# cyw20829 register map
Vendor: Infineon Technologies; Series: CYW20829; File version: 1.0
CPU: CM33 r0p1, little endian, MPU, no FPU, VTOR, 3 interrupt priority bits
Registers are 32-bit, read-write, reset 0x0 unless marked. A register's access mark holds for its fields unless they carry their own. Offsets are from the block's base; [hi:lo] are bit positions; lines under a group give offsets from that group; {n}, {i} and the like mark numbered series; 'fields as' and 'values as' point back to an identical list; <NAME> marks a mode.

## SRSS (part 2 of 2) — SRSS Core Registers
Base 0x40200000
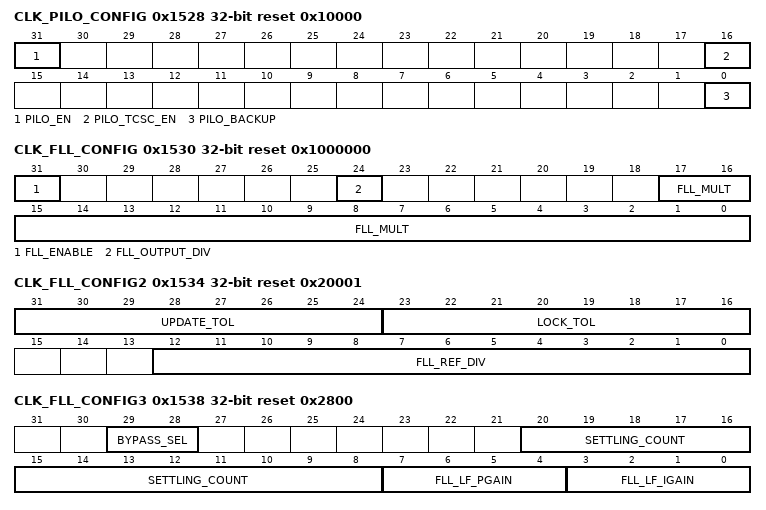
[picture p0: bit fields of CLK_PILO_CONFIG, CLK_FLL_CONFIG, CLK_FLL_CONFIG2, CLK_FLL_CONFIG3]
0x1528 CLK_PILO_CONFIG reset 0x10000 — Precision ILO Configuration Register
  [31] PILO_EN — Enable PILO. If the PILO is the selected source for WDT, writes to this field are ignored unless the WDT is unlocked using WDT_LOCK register.
  [16] PILO_TCSC_EN — PILO second order temperature curvature correction enable. If the PILO is the selected source for WDT, writes to this field are ignored unless the WDT is unlocked using WDT_LOCK register. 0: Disable second order temperature curvature correction. 1: Enable second order temperature curvature correction.
  [0] PILO_BACKUP — If backup domain is present on this product, this register indicates that PILO should stay enabled for use by backup domain during XRES, and HIBERNATE mode. If backup voltage domain is implemented on the product, PILO should stay enabled through power-related resets on other supplies, e.g.. BOD on VDDD/VCCD. If the PILO is the selected source for WDT, writes to this field are ignored unless the WDT is unlocked using WDT_LOCK register. 0: PILO turns off at XRES/BOD events. (unless backup voltage domain is implemented on the product) 1: PILO remains on if backup domain is present and powered even for XRES/BOD or HIBERNATE entry.
0x1530 CLK_FLL_CONFIG reset 0x1000000 — FLL Configuration Register
  [31] FLL_ENABLE — Master enable for FLL. The FLL requires firmware sequencing when enabling and disabling. Hardware handles sequencing automatically when entering/exiting DEEPSLEEP. To enable the FLL, use the following sequence: 1) Configure FLL and CCO settings. Do not modify CLK_FLL_CONFIG3.BYPASS_SEL (must be AUTO) or CLK_FLL_CONFIG.FLL_ENABLE (must be 0). 2) Enable the CCO by writing CLK_FLL_CONFIG4.CCO_ENABLE=1 3) Wait until CLK_FLL_STATUS.CCO_READY==1. 4) Ensure the reference clock has stabilized. 5) Write FLL_ENABLE=1. 6) Optionally wait until CLK_FLL_STATUS.LOCKED==1. The hardware automatically changes to the FLL output when LOCKED==1. To disable the FLL, use the following sequence: 1) Write CLK_FLL_CONFIG3.BYPASS_SEL=FLL_REF. 2) Read CLK_FLL_CONFIG3.BYPASS_SEL to ensure the write completes (read is not optional). 3) Wait at least ten cycles of either FLL reference clock or FLL output clock, whichever is slower. 4) Disable FLL with FLL_ENABLE=0. 5) Disable the CCO by writing CLK_FLL_CONFIG4.CCO_ENABLE=0. 6) Write CLK_FLL_CONFIG3.BYPASS_SEL=AUTO. 7) Read CLK_FLL_CONFIG3.BYPASS_SEL to ensure the write completes (read is not optional). 8) Wait three cycles of FLL reference clock. 0: Block is powered off 1: Block is powered on
  [24] FLL_OUTPUT_DIV — Control bits for Output divider. Set the divide value before enabling the FLL, and do not change it while FLL is enabled. 0: no division 1: divide by 2
  [17:0] FLL_MULT — Multiplier to determine CCO frequency in multiples of the frequency of the selected reference clock (Fref). Ffll = (FLL_MULT) * (Fref / REFERENCE_DIV) / (OUTPUT_DIV+1)
0x1534 CLK_FLL_CONFIG2 reset 0x20001 — FLL Configuration Register 2
  [31:24] UPDATE_TOL — Update tolerance sets the error threshold for when the FLL will update the CCO frequency settings. The update tolerance is the allowed difference between the count value for the ideal formula and the measured value. UPDATE_TOL should be less than LOCK_TOL.
  [23:16] LOCK_TOL — Lock tolerance sets the error threshold for when the FLL output is considered locked to the reference input. A high tolerance can be used to lock more quickly or allow less accuracy. The tolerance is the allowed difference between the count value for the ideal formula and the measured value. 0: tolerate error of 1 count value 1: tolerate error of 2 count values ... 255: tolerate error of 256 count values
  [12:0] FLL_REF_DIV — Control bits for reference divider. Set the divide value before enabling the FLL, and do not change it while FLL is enabled. 0: illegal (undefined behavior) 1: divide by 1 ... 8191: divide by 8191
0x1538 CLK_FLL_CONFIG3 reset 0x2800 — FLL Configuration Register 3
  [29:28] BYPASS_SEL — Bypass mux located just after FLL output. This register can be written while the FLL is enabled. When changing BYPASS_SEL, do not turn off the reference clock or CCO clock for five cycles (whichever is slower). Whenever BYPASS_SEL is changed, it is required to read CLK_FLL_CONFIG3 to ensure the change takes effect.
    0=AUTO (Automatic using lock indicator. When unlocked, automatically selects FLL reference input (bypass mode). When locked, automatically selects FLL output. This can allow some processing to occur while the FLL is locking, such as after DEEPSLEEP wakeup. It is incompatible with clock supervision, because the frequency changes based on the lock signal.); 1=LOCKED_OR_NOTHING (Similar to AUTO, except the clock is gated off when unlocked. This is compatible with clock supervision, because the supervisors allow no clock during startup (until a timeout occurs), and the clock targets the proper frequency whenever it is running.); 2=FLL_REF (Select FLL reference input (bypass mode). Ignores lock indicator); 3=FLL_OUT (Select FLL output. Ignores lock indicator.)
  [20:8] SETTLING_COUNT — Number of undivided reference clock cycles to wait after changing the CCO trim until the loop measurement restarts. A delay allows the CCO output to settle and gives a more accurate measurement. The default is tuned to an 8MHz reference clock since the IMO is expected to be the most common use case. 0: no settling time 1: wait one reference clock cycle ... 8191: wait 8191 reference clock cycles
  [7:4] FLL_LF_PGAIN — FLL Loop Filter Gain Setting #2. The proportional gain is the sum of FLL_LF_IGAIN and FLL_LF_PGAIN. 0: 1/256 1: 1/128 2: 1/64 3: 1/32 4: 1/16 5: 1/8 6: 1/4 7: 1/2 8: 1.0 9: 2.0 10: 4.0 11: 8.0 >=12: illegal
  [3:0] FLL_LF_IGAIN — FLL Loop Filter Gain Setting #1. The proportional gain is the sum of FLL_LF_IGAIN and FLL_LF_PGAIN. 0: 1/256 1: 1/128 2: 1/64 3: 1/32 4: 1/16 5: 1/8 6: 1/4 7: 1/2 8: 1.0 9: 2.0 10: 4.0 11: 8.0 >=12: illegal
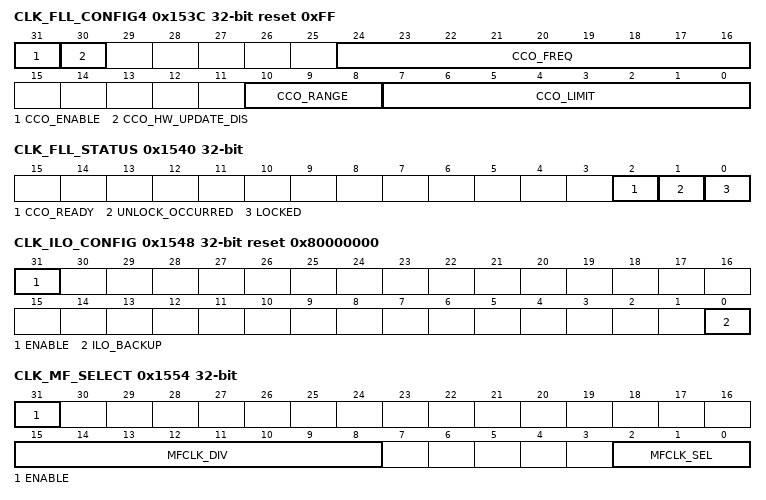
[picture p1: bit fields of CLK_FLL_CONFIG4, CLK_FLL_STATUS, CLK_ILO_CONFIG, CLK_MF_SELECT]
0x153C CLK_FLL_CONFIG4 reset 0xFF — FLL Configuration Register 4
  [31] CCO_ENABLE — Enable the CCO. It is required to enable the CCO before using the FLL. 0: Block is powered off 1: Block is powered on
  [30] CCO_HW_UPDATE_DIS — Disable CCO frequency update by FLL hardware 0: Hardware update of CCO settings is allowed. Use this setting for normal FLL operation. 1: Hardware update of CCO settings is disabled. Use this setting for open-loop FLL operation.
  [24:16] CCO_FREQ — CCO frequency code. This is updated by HW when the FLL is enabled. It can be manually updated to use the CCO in an open loop configuration. The meaning of each frequency code depends on the range.
  [10:8] CCO_RANGE — Frequency range of CCO
    0=RANGE0 (Target frequency is in range [48, 64) MHz); 1=RANGE1 (Target frequency is in range [64, 85) MHz); 2=RANGE2 (Target frequency is in range [85, 113) MHz); 3=RANGE3 (Target frequency is in range [113, 150) MHz); 4=RANGE4 (Target frequency is in range [150, 200] MHz)
  [7:0] CCO_LIMIT — Maximum CCO offset allowed (used to prevent FLL dynamics from selecting an CCO frequency that the logic cannot support)
0x1540 CLK_FLL_STATUS — FLL Status Register
  [2] CCO_READY ro — This indicates that the CCO is internally settled and ready to use.
  [1] UNLOCK_OCCURRED — This bit sets whenever the FLL is enabled and goes out of lock. This bit stays set until cleared by firmware. Note: When exiting Deep Sleep with FLL enabled, UNLOCK_OCCURRED will set. Therefore, after FLL successfully locks, FW should clear UNLOCK_OCCURRED flag to prevent a false positive that would indicate that FLL erroneously unlocked.
  [0] LOCKED ro — FLL Lock Indicator
0x1548 CLK_ILO_CONFIG reset 0x80000000 — ILO Configuration
  [31] ENABLE — Master enable for ILO. Writes to this field are ignored unless the WDT is unlocked using WDT_LOCK register. After enabling, it takes at most two cycles to reach the accuracy spec.
  [0] ILO_BACKUP — If backup domain is present on this product, this register indicates that ILO should stay enabled for use by backup domain during XRES, HIBERNATE mode, and through power-related resets like BOD on VDDD/VCCD. Writes to this field are ignored unless the WDT is unlocked using WDT_LOCK register. 0: ILO turns off at XRES/BOD event or HIBERNATE entry. 1: ILO remains on if backup domain is present and powered even for XRES/BOD or HIBERNATE entry.
0x154C CLK_TRIM_ILO_CTL reset 0x2C — ILO Trim Register
  [5:0] ILO_FTRIM — IL0 frequency trims. LSB step size is 1.5 percent (typical) of the frequency.
0x1554 CLK_MF_SELECT — Medium Frequency Clock Select Register
  [31] ENABLE — Enable for MFCLK (clk_mf). When disabling clk_mf, do not disable the source until after 5 clk_mf periods. clk_mf continues to operate in DEEPSLEEP for compatible sources. Firmware must disable clk_mf before entering DEEPSLEEP if the source is not compatible with DEEPSLEEP mode.
  [15:8] MFCLK_DIV — Divide selected clock source by (1+MFCLK_DIV). The output of this divider is MFCLK (clk_mf). Allows for integer divisions in the range [1, 256]. Do not change this setting while ENABLE==1.
  [2:0] MFCLK_SEL — Select source for MFCLK (clk_mf). Note that not all products support all clock sources. Selecting a clock source that is not supported results in undefined behavior.
    0=MFO (MFO - Medium Frequency Oscillator. DEEPSLEEP compatibility is product-specific. See CLK_MFO_CONFIG for capability of this product.); 1=ILO (ILO - Internal Low-speed Oscillator.); 2=WCO (WCO - Watch-Crystal Oscillator, if present.); 3=ALTLF (ALTLF - Alternate Low-Frequency Clock. Capability is product-specific); 4=PILO (PILO - Precision ILO, if present.); 5=ILO1 (ILO1 - Internal Low-speed Oscillator #1, if present.); 6=ECO_PRESCALER (ECO_PRESCALER - External-Crystal Oscillator, if present, after prescaling in CLK_ECO_PRESCALE. Intended for applications that operate in ACTIVE/SLEEP modes only. Does not work in DEEPSLEEP mode.); 7=LPECO (LPECO - Low Power External Crystal Oscillator, if present.)
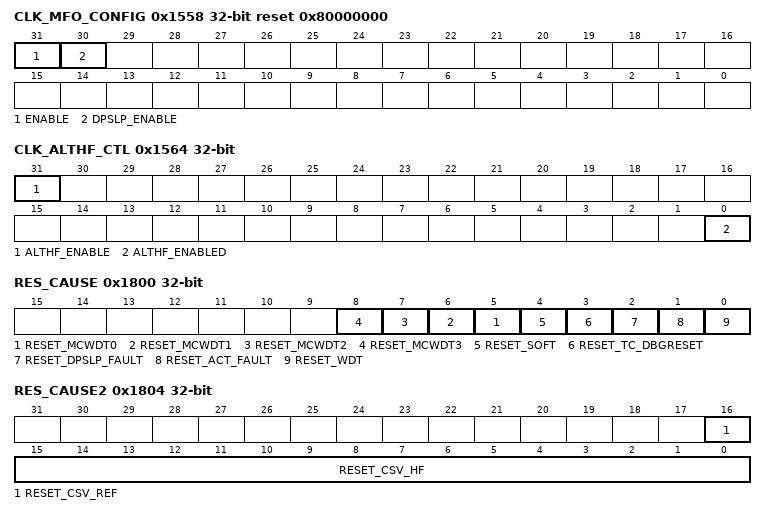
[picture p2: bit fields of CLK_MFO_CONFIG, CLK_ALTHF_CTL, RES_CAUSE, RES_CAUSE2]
0x1558 CLK_MFO_CONFIG reset 0x80000000 — MFO Configuration Register
  [31] ENABLE — Enable for Medium Frequency Oscillator (MFO) to generate clk_mf. It is product-specific whether this is a separate component or implemented as a divided version of another clock (eg. IMO).
  [30] DPSLP_ENABLE — Enable for MFO during DEEPSLEEP. This bit is ignored when ENABLE==0. When ENABLE==1: 0: MFO is automatically disabled during DEEPSLEEP and enables upon wakeup; 1: MFO is kept enabled throughout DEEPSLEEP
0x1560 CLK_IHO_CONFIG reset 0x80000000 — IHO Configuration Register
  [31] ENABLE — Enable for Internal High-speed Oscillator (IHO) to generate clk_iho.
0x1564 CLK_ALTHF_CTL — Alternate High Frequency Clock Control Register
  [31] ALTHF_ENABLE — Enable for ALTHF clock when used by SRSS. There may be independent control of ALTHF by another subsystem, and this bit prevents ALTHF from being disabled when SRSS needs it. SRSS automatically removes its enable request during DEEPSLEEP and lower modes.
  [0] ALTHF_ENABLED ro — Indicates that ALTHF is actually enabled. The delay between a transition on ALTHF_ENABLE and ALTHF_ENABLED is product specific.
0x1800 RES_CAUSE — Reset Cause Observation Register
  [n+5] RESET_MCWDT{n} (n=0..3) — Multi-Counter Watchdog timer reset #{n}. This is a low-voltage cause bit that hardware clears when the low-voltage supply is initialized (see comments above).
  [4] RESET_SOFT — A CPU requested a system reset through it's SYSRESETREQ. This can be done via a debugger probe or in firmware. This is a low-voltage cause bit that hardware clears when the low-voltage supply is initialized (see comments above).
  [3] RESET_TC_DBGRESET — Test controller or debugger asserted reset. Only resets debug domain. This is a low-voltage cause bit that hardware clears when the low-voltage supply is initialized (see comments above).
  [2] RESET_DPSLP_FAULT
  [1] RESET_ACT_FAULT
  [0] RESET_WDT — A basic WatchDog Timer (WDT) reset has occurred since last power cycle. ULP products: This is a low-voltage cause bit that hardware clears when the low-voltage supply is initialized (see comments above). For products that support high-voltage cause detection, this bit blocks recording of other high-voltage cause bits, except RESET_PORVDDD. Hardware clears this bit during POR. This bit is not blocked by other HV cause bits.
0x1804 RES_CAUSE2 — Reset Cause Observation Register 2
  [16] RESET_CSV_REF — Clock supervision logic requested a reset due to loss or frequency violation of the reference clock source that is used to monitor the other HF clock sources.
  [15:0] RESET_CSV_HF — Clock supervision logic requested a reset due to loss or frequency violation of a high-frequency clock. Each bit index K corresponds to a HFCLK<K>. Unimplemented clock bits return zero.
0x1814 RES_PXRES_CTL wo — Programmable XRES Control Register
  [0] PXRES_TRIGGER — Triggers PXRES. This causes a full-scope reset and reboot.
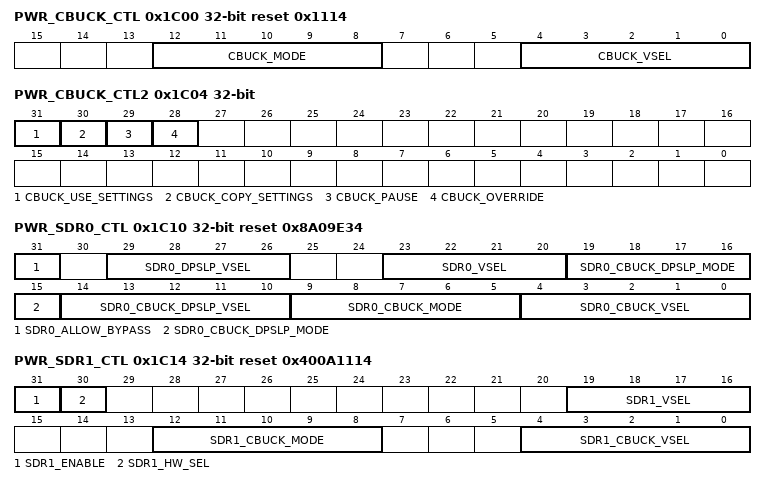
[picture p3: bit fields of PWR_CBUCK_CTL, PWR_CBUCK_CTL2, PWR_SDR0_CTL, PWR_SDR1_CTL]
0x1C00 PWR_CBUCK_CTL reset 0x1114 — Core Buck Control Register
  [12:8] CBUCK_MODE — CBUCK mode. Low ripple (high power) modes are intended for analog that needs low ripple. Low power mode is suitable for digital processing. The CBUCK mode is defined as = {mode*_sr_mode, mode*_sr_hp_submode[1:0], mode*_sr_lp_submode[1:0]} The actual CBUCK mode is the maximum of this setting and the settings of all enabled step-down regulators. 0x11: HP, PFM Auto, High-Low (default Active) 0x01: LP, PFM Auto, High-Low (DeepSleep) See s40power BROS for other settings
  [4:0] CBUCK_VSEL — Voltage output selection. This register is only reset by XRES, HIBERNATE wakeup, or supply supervision reset. The actual CBUCK voltage is the maximum of this setting, the settings for all enabled step-down regulators (see PWR_SDR*_CTL), and the minimum DEEPSLEEP setting (which is not user configurable). These settings follow the formula (0.76+0.02*CBUCK_VSEL). 0: 0.76V, 1: 0.78V, 2: 0.80V, 3: 0.82V, 4: 0.84V, 5: 0.86V, 6: 0.88V, 7: 0.90V, 8: 0.92V, 9: 0.94V, 10: 0.96V, 11: 0.98V, 12: 1.00V, 13: 1.02V, 14: 1.04V, 15: 1.06V, 16: 1.08V, 17: 1.10V, 18: 1.12V, 19: 1.14V, 20: 1.16V, 21: 1.18V, 22: 1.20V, 23: 1.22V, 24: 1.24V, 25: 1.26V, 26: 1.28V, 27: 1.30V, 28: 1.32V, 29: 1.34V, 30: 1.36V, 31: 1.38V.
0x1C04 PWR_CBUCK_CTL2 — Core Buck Control Register 2
  [31] CBUCK_USE_SETTINGS — Causes the settings in PWR_CBUCK_CTL register to be included in the CBUCK setting decision. Can be used to override the normal hardware voltage behavior. Regardless of this bit, the extra settings in PWR_CBUCK_CTL register are not used during DEEPSLEEP.
  [30] CBUCK_COPY_SETTINGS — Copies the current CBUCK composite state to the fields in PWR_CBUCK_CTL register (CBUCK_VSEL and CBUCK_MODE). It is recommended to pause transitions using CBUCK_PAUSE to ensure the state does not change near the copy. After it is copied, the CBUCK_OVERRIDE bit can be used to hold the CBUCK in the current state. Note, reading this bit always returns 0. 0: no change 1: copy settings.
  [29] CBUCK_PAUSE — Pauses new dynamic CBUCK transitions. An already started transition will complete, but new dynamic transitions are paused. This can be used as part of a firmware sequence to change the voltage setting of an enabled stepdown regulator.
  [28] CBUCK_OVERRIDE — Forces the CBUCK to use the settings in PWR_CBUCK_CTL register, ignoring the other hardware requests. This can be used as part of a firmware algorithm to change the voltage of an enabled stepdown regulator. This bit is cleared by any reset.
0x1C08 PWR_CBUCK_CTL3 — Core Buck Control Register 3
  [31] CBUCK_INRUSH_SEL — CBUCK inrush limit selection. 0: 10mA limit. 1: 100mA limit.
0x1C0C PWR_CBUCK_STATUS ro — Core Buck Status Register
  [31] PMU_DONE — Indicates the power management unit is finished with a transition. 0: PMU busy 1: PMU done
0x1C10 PWR_SDR0_CTL reset 0x8A09E34 — Step Down Regulator 0 Control Register
  [31] SDR0_ALLOW_BYPASS — SDR0 bypass control. 0: Force SDR0 to regulate. 1: Allow SDR0 to bypass if the actual CBUCK voltage matches SDR0_CBUCK_VSEL.
  [29:26] SDR0_DPSLP_VSEL — SDR0 output voltage during DeepSleep. (See SDR0_VSEL for voltage table).
  [23:20] SDR0_VSEL — SDR0 output voltage. 0: 0.850V, 1: 0.875V, 2: 0.900V, 3: 0.925V, 4: 0.950V, 5: 0.975V, 6: 1.000V, 7: 1.025V, 8: 1.050V, 9: 1.075V, 10: 1.100V, 11: 1.125V, 12: 1.150V, 13: 1.175V, 14: 1.200V, 15: 1.225V
  [19:15] SDR0_CBUCK_DPSLP_MODE — DeepSleep CBUCK mode when using SDR0 (see PWR_CBUCK_CTL for mode table). Default DeepSleep
  [14:10] SDR0_CBUCK_DPSLP_VSEL — DeepSleep voltage selection of CBUCK (see PWR_CBUCK_CTL for voltage table). The voltage must be 60mV higher than the SDR output or the regulator output may bypass.
  [9:5] SDR0_CBUCK_MODE — Minimum CBUCK mode when using SDR0 (see PWR_CBUCK_CTL for mode table). Default Active
  [4:0] SDR0_CBUCK_VSEL — Minimum voltage selection of CBUCK when using this SDR0 (see PWR_CBUCK_CTL for voltage table). The voltage must be 60mV higher than the SDR output or the regulator output may bypass.
0x1C14 PWR_SDR1_CTL reset 0x400A1114 — Step Down Regulator 1 Control Register
  [31] SDR1_ENABLE — Enable for SDR1.
  [30] SDR1_HW_SEL — Selects hardware control for SDR1. 0: SDR1_ENABLE controls SDR1. Hardware controls are ignored. 1: SDR1_ENABLE is ignored and a hardware signal is used instead. Selecting this on products that don't have supporting hardware will disable SDR1.
  [19:16] SDR1_VSEL — SDR1 output voltage. 0: 0.850V, 1: 0.875V, 2: 0.900V, 3: 0.925V, 4: 0.950V, 5: 0.975V, 6: 1.000V, 7: 1.025V, 8: 1.050V, 9: 1.075V, 10: 1.100V, 11: 1.125V, 12: 1.150V, 13: 1.175V, 14: 1.200V, 15: 1.225V
  [12:8] SDR1_CBUCK_MODE — Minimum CBUCK mode when using SDR1 (see PWR_CBUCK_CTL for mode table).
  [4:0] SDR1_CBUCK_VSEL — Minimum voltage selection of CBUCK when using this SDR1 (see PWR_CBUCK_CTL for voltage table). The voltage must be 60mV higher than the SDR output or the regulator output may bypass.
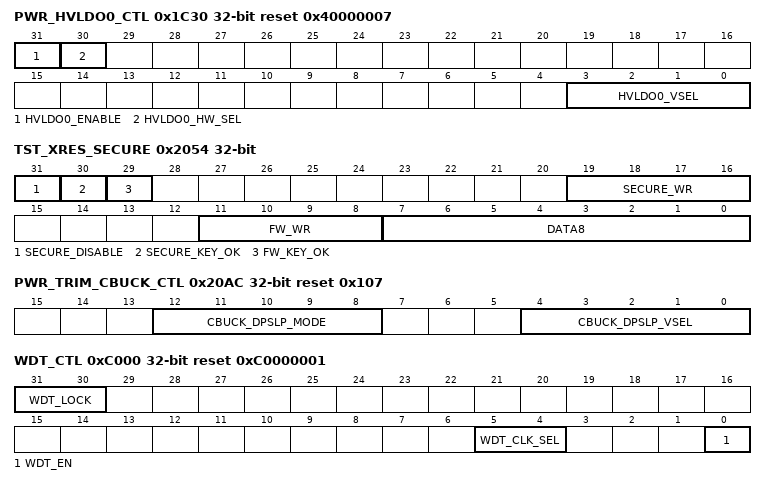
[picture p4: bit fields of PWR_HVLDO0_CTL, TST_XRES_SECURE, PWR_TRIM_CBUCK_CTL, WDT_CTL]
0x1C30 PWR_HVLDO0_CTL reset 0x40000007 — HVLDO0 Control Register
  [31] HVLDO0_ENABLE
  [30] HVLDO0_HW_SEL — Selects hardware control for HVLDO0. 0: HVLDO0_ENABLE controls SDR1. Hardware controls are ignored. 1: HVLDO0_ENABLE is ignored and a hardware signal is used instead. Selecting this on products that don't have supporting hardware will disable HVLDO0.
  [3:0] HVLDO0_VSEL — HVLDO0 output voltage. 0: 1.8V, 1: 1.9V, 2: 2.0V, 3: 2.1V, 4: 2.2V, 5: 2.3V, 6: 2.4V, 7: 2.5V, 8: 2.6V, 9: 2.7V, 10: 2.8V, 11: 2.9V, 12: 3.0V, 13: 3.1V, 14: 3.2V, 15: 3.3V
0x2054 TST_XRES_SECURE — SECURE TEST and FIRMWARE TEST Key control register
  [31] SECURE_DISABLE — Disables the SECURE TEST key entry capability until next reset. Must not be set in the same write when any of the above *_WR bits are set or toggling.
  [30] SECURE_KEY_OK ro — Indicates that the 32-bit SECURE TEST key is observing the correct key. Secure key is not reset, but it will establish low after a deep power cycle that causes it to lose its written state.
  [29] FW_KEY_OK ro — Indicates that the 32-bit FIRMWARE TEST key is observing the correct key. Firmware key is reset by (A)XRES and STRUCT_XRES.
  [19:16] SECURE_WR — Latch enables for each of the 4 bytes in the 32-bit SECURE TEST key. Must be toggled high and then low while keeping DATA8 to the correct value.
  [11:8] FW_WR — Latch enables for each of the 4 bytes in the 32-bit FIRMWARE TEST key. Must be toggled high and then low while keeping DATA8 to the correct value.
  [7:0] DATA8 — Data byte to be set into either SECURE TEST or FIRMWARE TEST key. Must not be changed in the same write that is toggling any of the *_WR bits below,
0x20AC PWR_TRIM_CBUCK_CTL reset 0x107 — CBUCK Trim Register
  [12:8] CBUCK_DPSLP_MODE — The CBUCK mode setting to use during DEEPSLEEP.
  [4:0] CBUCK_DPSLP_VSEL — The CBUCK voltage setting to use during DEEPSLEEP.
0xC000 WDT_CTL reset 0xC0000001 — Watchdog Counter Control Register (Type A)
  [31:30] WDT_LOCK — Prohibits writing to WDT_*, CLK_ILO_CONFIG, CLK_SELECT.LFCLK_SEL, and CLK_TRIM_ILO_CTL registers when not equal 0. Requires at least two different writes to unlock. A change in WDT_LOCK takes effect beginning with the next write cycle. Note that this field is 2 bits to force multiple writes only. It represents only a single write protect signal protecting all those registers at the same time. WDT will lock on any reset. This field is not retained during DEEPSLEEP or HIBERNATE mode, so the WDT will be locked after wakeup from these modes.
    0=NO_CHG (No effect); 1=CLR0 (Clears bit 0); 2=CLR1 (Clears bit 1); 3=SET01 (Sets both bits 0 and 1)
  [5:4] WDT_CLK_SEL — Select source for WDT. Not all products support all clock sources. Selecting a clock source that is not supported will result in undefined behavior. Writes to this field are ignored unless the WDT is unlock using WDT_LOCK register. It takes four cycles of the originally selected clock to switch away from it. Do not disable the original clock during this time.
    0=ILO (ILO - Internal Low-speed Oscillator); 1=PILO (PILO - Precision ILO. If present, if present); 2=BAK (BAK - Selected clk_bak source, if present. See BACKUP_CTL. This choice is not recommended for applications that rely upon the watchdog timer for safety or security, unless the product supports clock supervision of clk_bak (CSV_BAK). Generation of clk_bak is not protected by WDT_LOCK and is in a different memory region with potentially different security attributes.)
  [0] WDT_EN — Enable this watchdog timer. This field is retained during DEEPSLEEP and HIBERNATE modes.
0xC004 WDT_CNT — Watchdog Counter Count Register (Type A)
  [31:0] COUNTER — Current value of WDT Counter. The write feature of this register is for engineering use (DfV), have no synchronization, and can only be applied when the WDT is fully off. When writing, the value is updated immediately in the WDT counter, but it will read back as the old value until this register resynchronizes just after the negedge of ILO. Writes will be ignored if they occur when the WDT is enabled.
0xC008 WDT_MATCH reset 0x1000 — Watchdog Counter Match Register (Type A)
  [31:0] MATCH — Match value for Watchdog counter. Every time WDT_COUNTER reaches MATCH an interrupt is generated. Two unserviced interrupts will lead to a system reset (i.e. at the third match).
0xC00C WDT_MATCH2 reset 0x1F — Watchdog Counter Match Register 2 (Type A)
  [4:0] IGNORE_BITS_ABOVE — The bit index to be considered the MSB for matching. Bit indices above this setting are NOT checked against MATCH. This value provides control over the time-to-reset of the watchdog (which happens after 3 successive matches). The four LSBs cannot be ignored for matching. Settings <3 behave like a setting of 3. If the setting is higher than the number of bits in the WDT counter, all actual bits in the counter are matched.
0xD000 MCWDT_STRUCT group — Multi-Counter Watchdog Timer (Type A)
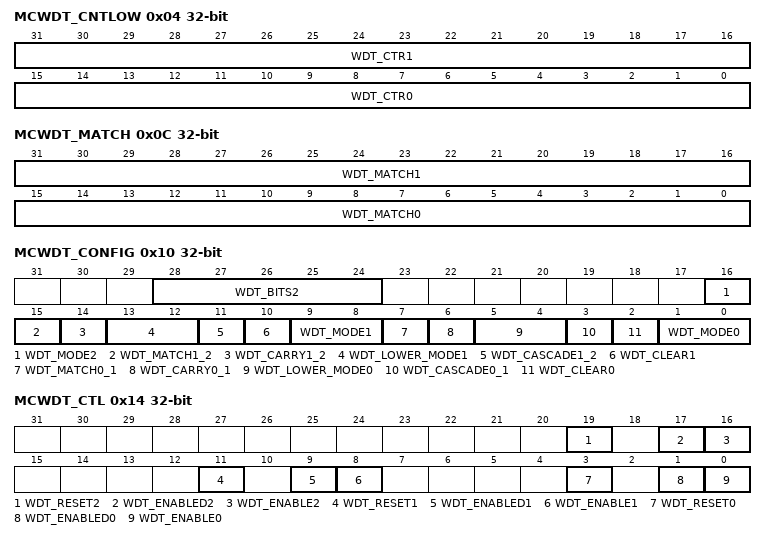
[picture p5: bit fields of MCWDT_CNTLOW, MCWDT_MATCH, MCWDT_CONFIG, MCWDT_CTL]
  0x04 MCWDT_CNTLOW — Multi-Counter Watchdog Sub-counters 0/1
    [31:16] WDT_CTR1 — Current value of sub-counter 1 for this MCWDT. Software writes are ignored when the sub-counter is enabled
    [15:0] WDT_CTR0 — Current value of sub-counter 0 for this MCWDT. Software writes are ignored when the sub-counter is enabled.
  0x08 MCWDT_CNTHIGH — Multi-Counter Watchdog Sub-counter 2
    [31:0] WDT_CTR2 — Current value of sub-counter 2 for this MCWDT. Software writes are ignored when the sub-counter is enabled
  0x0C MCWDT_MATCH — Multi-Counter Watchdog Counter Match Register
    [31:16] WDT_MATCH1 — Match value for sub-counter 1 of this MCWDT
    [15:0] WDT_MATCH0 — Match value for sub-counter 0 of this MCWDT
  0x10 MCWDT_CONFIG — Multi-Counter Watchdog Counter Configuration
    [28:24] WDT_BITS2 — Bit to observe for WDT_INT2: 0: Assert after bit0 of WDT_CTR2 toggles (one int every tick) ... 31: Assert after bit31 of WDT_CTR2 toggles (one int every 2^31 ticks)
    [16] WDT_MODE2 — Watchdog Counter 2 Mode.
      0=NOTHING (Free running counter with no interrupt requests); 1=INT (Free running counter with interrupt request that occurs one LFCLK cycle after the specified bit in CTR2 toggles (see WDT_BITS2).)
    [15] WDT_MATCH1_2 — Specifies matching behavior when WDT_CASCADE1_2==1. When WDT_CASCADE1_2==0, this bit is not used and match is based on counter 2 alone. 0: Match based on counter 2 alone. 1: Match based on counter 2 and counter 1 matching simultaneously.
    [14] WDT_CARRY1_2 — Carry out behavior that applies when WDT_CASCADE1_2==1. This bit is not used when WDT_CASCADE1_2==0. 0: carry out on counter 1 match. 1: carry out on counter 1 roll-over.
    [13:12] WDT_LOWER_MODE1 — Watchdog Counter Action on service before lower limit.
      0=NOTHING (Do nothing); 1=INT (Assert WDT_INTx); 2=RESET (Assert WDT Reset)
    [11] WDT_CASCADE1_2 — Cascade Watchdog Counters 1,2. Counter 2 increments the cycle after WDT_CTR1=WDT_MATCH1. It is allowed to cascade all three WDT counters. 0: Independent counters 1: Cascaded counters. When cascading all three counters, WDT_CLEAR1 must be 1.
    [10] WDT_CLEAR1 — Clear Watchdog Counter when WDT_CTR1==WDT_MATCH1. In other words WDT_CTR1 divides LFCLK by (WDT_MATCH1+1). 0: Free running counter 1: Clear on match. In this mode, the minimum legal setting of WDT_MATCH1 is 1.
    [9:8] WDT_MODE1 — Watchdog Counter Action on Match. Action is taken on the next increment after the values match (WDT_CTR1=WDT_MATCH1).
      0=NOTHING (Do nothing); 1=INT (Assert WDT_INTx); 2=RESET (Assert WDT Reset); 3=INT_THEN_RESET (Assert WDT_INTx, assert WDT Reset after 3rd unhandled interrupt)
    [7] WDT_MATCH0_1 — Specifies matching behavior when WDT_CASCADE0_1==1. When WDT_CASCADE0_1==0, this bit is not used and match is based on counter 1 alone. 0: Match based on counter 1 alone. 1: Match based on counter 1 and counter 0 matching simultaneously.
    [6] WDT_CARRY0_1 — Carry out behavior that applies when WDT_CASCADE0_1==1. This bit is not used when WDT_CASCADE0_1==0. 0: carry out on counter 0 match. 1: carry out on counter 0 roll-over.
    [5:4] WDT_LOWER_MODE0 — Watchdog Counter Action on service before lower limit.
      values as WDT_LOWER_MODE1
    [3] WDT_CASCADE0_1 — Cascade Watchdog Counters 0,1. Counter 1 increments the cycle after WDT_CTR0=WDT_MATCH0. 0: Independent counters 1: Cascaded counters
    [2] WDT_CLEAR0 — Clear Watchdog Counter when WDT_CTR0=WDT_MATCH0. In other words WDT_CTR0 divides LFCLK by (WDT_MATCH0+1). 0: Free running counter 1: Clear on match. In this mode, the minimum legal setting of WDT_MATCH0 is 1.
    [1:0] WDT_MODE0 — Watchdog Counter Action on Match. Action is taken on the next increment after the values match (WDT_CTR0=WDT_MATCH0).
      values as WDT_MODE1
  0x14 MCWDT_CTL — Multi-Counter Watchdog Counter Control
    [19] WDT_RESET2 — Resets counter 2 back to 0000. Hardware will reset this bit after counter was reset. This will take up to one LFCLK cycle to take effect.
    [17] WDT_ENABLED2 ro — Indicates actual state of counter. May lag WDT_ENABLE2 by up to two LFCLK cycles.
    [16] WDT_ENABLE2 — Enable subcounter 2. May take up to 2 LFCLK cycles to take effect. 0: Counter is disabled (not clocked) 1: Counter is enabled (counting up)
    [11] WDT_RESET1 — Resets counter 1 back to 0000. Hardware will reset this bit after counter was reset. This will take up to one LFCLK cycle to take effect.
    [9] WDT_ENABLED1 ro — Indicates actual state of counter. May lag WDT_ENABLE1 by up to two LFCLK cycles.
    [8] WDT_ENABLE1 — Enable subcounter 1. May take up to 2 LFCLK cycles to take effect. 0: Counter is disabled (not clocked) 1: Counter is enabled (counting up)
    [3] WDT_RESET0 — Resets counter 0 back to 0000. Hardware will reset this bit after counter was reset. This will take up to one LFCLK cycle to take effect.
    [1] WDT_ENABLED0 ro — Indicates actual state of counter. May lag WDT_ENABLE0 by up to two LFCLK cycles.
    [0] WDT_ENABLE0 — Enable subcounter 0. May take up to 2 LFCLK cycles to take effect. 0: Counter is disabled (not clocked) 1: Counter is enabled (counting up)
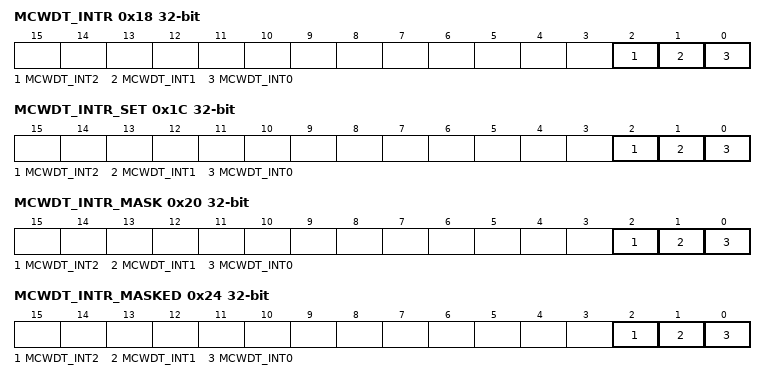
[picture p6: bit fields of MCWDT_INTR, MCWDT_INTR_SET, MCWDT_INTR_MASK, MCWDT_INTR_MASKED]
  0x18 MCWDT_INTR — Multi-Counter Watchdog Counter Interrupt Register
    [2] MCWDT_INT2 — MCWDT Interrupt Request for sub-counter 2. This bit is set by hardware as configured by this registers. This bit must be cleared by firmware. Clearing this bit also prevents Reset from happening when WDT_MODE2=3.
    [1] MCWDT_INT1 — MCWDT Interrupt Request for sub-counter 1. This bit is set by hardware as configured by this registers. This bit must be cleared by firmware. Clearing this bit also prevents Reset from happening when WDT_MODE1=3.
    [0] MCWDT_INT0 — MCWDT Interrupt Request for sub-counter 0. This bit is set by hardware as configured by this registers. This bit must be cleared by firmware. Clearing this bit also prevents Reset from happening when WDT_MODE0=3.
  0x1C MCWDT_INTR_SET — Multi-Counter Watchdog Counter Interrupt Set Register
    [2] MCWDT_INT2 — Set interrupt for MCWDT_INT2
    [1] MCWDT_INT1 — Set interrupt for MCWDT_INT1
    [0] MCWDT_INT0 — Set interrupt for MCWDT_INT0
  0x20 MCWDT_INTR_MASK — Multi-Counter Watchdog Counter Interrupt Mask Register
    [2] MCWDT_INT2 — Mask for sub-counter 2. This controls if the interrupt is forwarded to the CPU. 0: Interrupt is masked (not forwarded). 1: Interrupt is forwarded.
    [1] MCWDT_INT1 — Mask for sub-counter 1. This controls if the interrupt is forwarded to the CPU. 0: Interrupt is masked (not forwarded). 1: Interrupt is forwarded.
    [0] MCWDT_INT0 — Mask for sub-counter 0. This controls if the interrupt is forwarded to the CPU. 0: Interrupt is masked (not forwarded). 1: Interrupt is forwarded.
  0x24 MCWDT_INTR_MASKED ro — Multi-Counter Watchdog Counter Interrupt Masked Register
    [2] MCWDT_INT2 — Logical and of corresponding request and mask bits.
    [1] MCWDT_INT1 — Logical and of corresponding request and mask bits.
    [0] MCWDT_INT0 — Logical and of corresponding request and mask bits.
  0x28 MCWDT_LOCK — Multi-Counter Watchdog Counter Lock Register
    [31:30] MCWDT_LOCK — Prohibits writing control and configuration registers related to this MCWDT when not equal 0 (as specified in the other register descriptions). Requires at least two different writes to unlock. Note that this field is 2 bits to force multiple writes only. Each MCWDT has a separate local lock. LFCLK settings are locked by the global WDT_LOCK register, and this register has no effect on that.
      values as WDT_CTL.WDT_LOCK
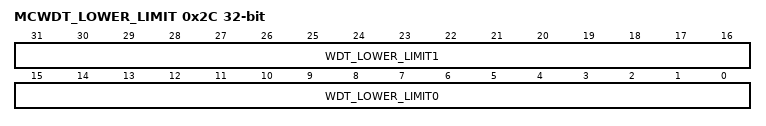
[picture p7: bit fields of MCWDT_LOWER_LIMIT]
  0x2C MCWDT_LOWER_LIMIT — Multi-Counter Watchdog Counter Lower Limit Register
    [31:16] WDT_LOWER_LIMIT1 — Lower limit for sub-counter 1 of this MCWDT
    [15:0] WDT_LOWER_LIMIT0 — Lower limit for sub-counter 0 of this MCWDT
